# S32K324_M7 register map
Vendor: NXP Semiconductors; File version: 1.1
CPU: CM7 r0p1, little endian, MPU, FPU, VTOR, 4 interrupt priority bits
Registers are 32-bit, read-write, reset 0x0 unless marked. A register's access mark holds for its fields unless they carry their own. Offsets are from the block's base; [hi:lo] are bit positions; lines under a group give offsets from that group; {n}, {i} and the like mark numbered series.

## STM_0 — STM
Base 0x40274000
Same registers: STM_1 0x40474000
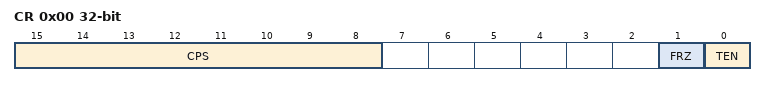
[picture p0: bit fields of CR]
0x00 CR — Control
  [15:8] CPS — Counter Prescaler
  [1] FRZ — Freeze
    0=runs (Timer runs in Debug mode); 1=stop (Timer stops in Debug mode)
  [0] TEN — Timer Enable
    0=disabled; 1=enabled
0x04 CNT — Count
  [31:0] CNT — Timer Count
{0x10+0x10*i} CHANNEL[{i}] (i=0..3) group
  0x00 CCR — Channel Control
    [0] CEN — Channel Enable
      0=disabled; 1=enabled
  0x04 CIR write-1-clears — Channel Interrupt
    [0] CIF write-1-clears — Channel Interrupt Flag
      0=no_irq (Read: IRQ is not asserted. Write: No effect.); 1=irq (Read: IRQ is asserted. Write: Clear the flag.)
  0x08 CMP — Channel Compare

## INTM
Base 0x4027C000
0x00 INTM_MM — Monitor Mode
  [0] MM
    0=disabled; 1=enabled
0x04 INTM_IACK wo — Interrupt Acknowledge
  [9:0] IRQ — This field is used to specify the interrupt request number to stop INTM_TIMERa.
{0x8+0x10*i} mon[{i}] (i=0..3) group
  0x00 INTM_IRQSEL — Interrupt Request Select mon_index
    [9:0] IRQ — This field helps you select the interrupt request number to monitor.
  0x04 INTM_LATENCY — INTM_LATENCYmon_index
    [23:0] LAT — This field helps you select the maximum number of INTM clock cycles allowed for the monitored interrupt request
  0x08 INTM_TIMER — Timer mon_index
    [23:0] TIMER — This field is used to count the number of INTM clock cycles up to 24 bits of resolution.
  0x0C INTM_STATUS ro — Status mon_index
    [0] STATUS — Monitor status
      0=ST02 (INTM_TIMER value has not exceeded the INTM_LATENCY value.); 1=ST01 (INTM_TIMER value has exceeded the INTM_LATENCY value.)

## DMAMUX_0 — DMAMUX
Base 0x40280000
Same registers: DMAMUX_1 0x40284000
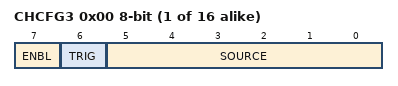
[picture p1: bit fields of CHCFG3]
0x00 CHCFG{x} (x=3,2,1,0,7,6,5,4,11,10,9,8,15,14,13,12; step 0x1) 8-bit — Channel Configuration register
  [7] ENBL — DMA Channel Enable
    0=DISABLE (DMA channel is disabled. This mode is primarily used during configuration of the DMAMUX. The DMA has separate channel enables/disables, which should be used to disable or reconfigure a DMA channel.); 1=ENABLE (DMA channel is enabled)
  [6] TRIG — DMA Channel Trigger Enable
    0=DISABLE (Triggering is disabled. If triggering is disabled and ENBL is set, the DMA Channel will simply route the specified source to the DMA channel. (Normal mode)); 1=ENABLE (Triggering is enabled. If triggering is enabled and ENBL is set, the DMAMUX is in Periodic Trigger mode.)
  [5:0] SOURCE — DMA Channel Source (Slot)

## RTC
Base 0x40288000
0x00 RTCSUPV reset 0x80000000 — RTC Supervisor control register
  [31] SUPV — RTC Supervisor Bit.
    0=All registers are accessible in both user as well as supervisor mode; 1=All other registers are accessible in the supervisor mode only
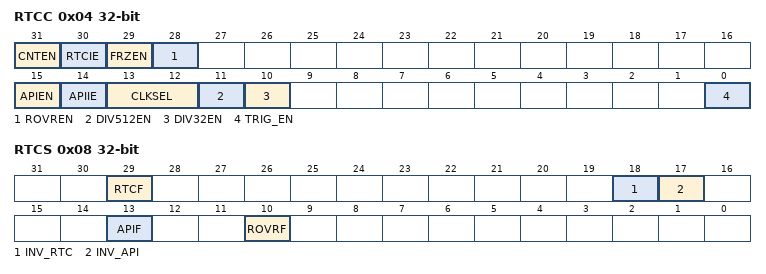
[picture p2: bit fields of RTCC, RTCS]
0x04 RTCC — RTC Control register
  [31] CNTEN — Counter Enable
    0=Counter disabled; 1=Counter enabled
  [30] RTCIE — RTC Interrupt Enable.
    0=RTC interrupts disabled; 1=RTC interrupts enabled
  [29] FRZEN — Freeze Enable Bit
    0=Counter does not freeze in debug mode; 1=Counter freezes in debug mode
  [28] ROVREN — Counter Roll Over wakeup/Interrupt Enable.
    0=RTC rollover wakeup/interrupt disabled; 1=RTC rollover wakeup/interrupt enabled
  [15] APIEN — Autonomous Periodic Interrupt Enable.
    0=API disabled; 1=API enabled
  [14] APIIE — API Interrupt Enable.
    0=API interrupts disabled; 1=API interrupts enabled
  [13:12] CLKSEL — Clock select
    {v}=Clock source {v} (v=0..3)
  [11] DIV512EN — Divide by 512 enable
    0=Divide by 512 is disabled; 1=Divide by 512 is enabled
  [10] DIV32EN — Divide by 32 enable.
    0=Divide by 32 is disabled; 1=Divide by 32 is enabled
  [0] TRIG_EN — Trigger enable for Analog Comparator
0x08 RTCS — RTC Status register
  [29] RTCF write-1-clears — RTC Interrupt Flag
    0=RTC counter is not equal to RTCVAL; 1=RTC counter matches RTCVAL
  [18] INV_RTC ro — Invalid RTC write
  [17] INV_API ro — Invalid APIVAL write
  [13] APIF write-1-clears — API Interrupt Flag.
    0=Counter is not equal to API offset value; 1=Counter matches the API offset value
  [10] ROVRF write-1-clears — Counter Roll Over Interrupt Flag.
    0=RTC has not rolled over; 1=RTC has rolled over
0x0C RTCCNT ro — RTC Counter register
  [31:0] RTCCNT — RTC Counter Value
0x10 APIVAL — API Compare value register
  [31:0] APIVAL — API Compare Value.
0x14 RTCVAL — RTC Compare value register
  [31:0] RTCVAL — RTC Compare Value.
